# A64 register map
Vendor: Allwinner; Series: A64; File version: 0.1
CPU: CA53 0, little endian, MPU, no FPU, 0 interrupt priority bits
Registers are 32-bit, read-write, reset 0x0 unless marked. A register's access mark holds for its fields unless they carry their own. Offsets are from the block's base; [hi:lo] are bit positions; 'fields as' and 'values as' point back to an identical list.

## High_Speed_Timer
Base 0x01C60000
0x00 HS_TMR_IRQ_EN_REG — HS Timer IRQ Enable Register
  [0] HS_TMR_INT_EN — High Speed Timer Interrupt Enable. 0: No effect; 1: High Speed Timer Interval Value reached interrupt enable.
    0=No_effect; 1=High Speed Timer Interval Value reached interrupt enable
0x04 HS_TMR_IRQ_STAS_REG — HS Timer Status Register
  [0] HS_TMR_IRQ_PEND — High Speed Timer IRQ Pending. Set 1 to the bit will clear it. 0: No effect; 1: Pending, High speed timer interval value is reached.
    0=No_effect; 1=Pending, High speed timer interval value is reached
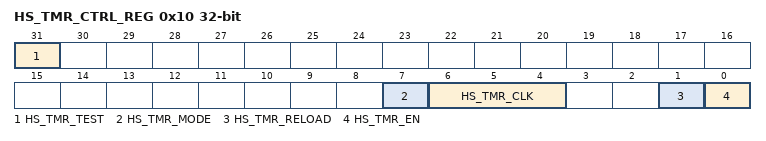
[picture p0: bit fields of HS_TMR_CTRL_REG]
0x10 HS_TMR_CTRL_REG — HS Timer Control Register
  [31] HS_TMR_TEST — High speed timer test mode. In test mode, the low register should be set to 0x1, the high register will down counter. The counter needs to be reloaded. 0: normal mode; 1: test mode.
    0=normal mode;; 1=test mode
  [7] HS_TMR_MODE — High Speed Timer mode. 0: Continuous mode. When interval value reached, the timer will not disable automatically. 1: Single mode. When interval value reached, the timer will disable automatically.
    0=Continuous mode. When interval value reached, the timer will not disable automatically.; 1=Single mode. When interval value reached, the timer will disable automatically.
  [6:4] HS_TMR_CLK — Select the pre-scale of the high speed timer clock sources. 000: /1 001: /2 010: /4 011: /8 100: /16 101: / 110: / 111: /
    0=_slash_1 (/1); 1=_slash_2 (/2); 2=_slash_4 (/4); 3=_slash_8 (/8); 4=_slash_16 (/16)
  [1] HS_TMR_RELOAD — High Speed Timer Reload. 0: No effect 1: Reload High Speed Timer Interval Value.
    0=No_effect; 1=Reload High Speed Timer Interval Value
  [0] HS_TMR_EN — High Speed Timer Enable. 0: Stop/Pause 1: Start. If the timer is started, it will reload the interval value to internal register, and the current counter will count from interval value to 0. If the current counter does not reach the zero, the timer enable bit is set to `0`, the current value counter will pause. At least wait for 2 cycles, the start bit can be set to 1. In timer pause state, the interval value register can be modified. If the timer is started again, and the Software hope the current value register to down-count from the new interval value, the reload bit and the enable bit should be set to 1 at the same time.
    0=Stop_slash_Pause (Stop/Pause); 1=Start. If the timer is started, it will reload the interval value to internal register, and the current counter will count from interval value to 0. If the current counter does not reach the zero, the timer enable bit is set to `0`, the current value counter will pause. At least wait for 2 cycles, the start bit can be set to 1. In timer pause state, the interval value register can be modified. If the timer is started again, and the Software hope the current value register to down-count from the new interval value, the reload bit and the enable bit should be set to 1 at the same time.
0x14 HS_TMR_INTV_LO_REG reset not defined — HS Timer Interval Value Low Register
  [31:0] HS_TMR_INTV_VALUE_LO — High Speed Timer Interval Value [31:0].
0x18 HS_TMR_INTV_HI_REG reset not defined — HS Timer Interval Value High Register
  [23:0] HS_TMR_INTV_VALUE_HI — High Speed Timer Interval Value [55:32].
0x1C HS_TMR_CURNT_LO_REG reset not defined — HS Timer Current Value Low Register
  [31:0] HS_TMR_CUR_VALUE_LO — High Speed Timer Current Value [31:0].
0x20 HS_TMR_CURNT_HI_REG reset not defined — HS Timer Current Value High Register
  [23:0] HS_TMR_CUR_VALUE_HI — High Speed Timer Current Value [55:32].

## KEYADC
Base 0x01C21800
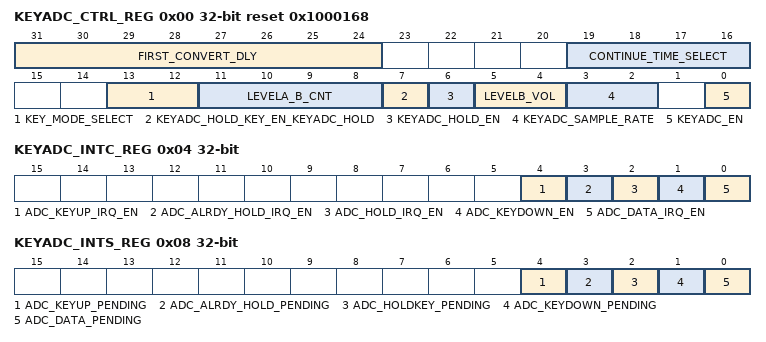
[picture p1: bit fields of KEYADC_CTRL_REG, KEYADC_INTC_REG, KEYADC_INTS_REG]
0x00 KEYADC_CTRL_REG reset 0x1000168
  [31:24] FIRST_CONVERT_DLY — FIRST_CONVERT_DLY. ADC First Convert Delay setting, ADC conversion is delayed by n samples
  [19:16] CONTINUE_TIME_SELECT — CONTINUE_TIME_SELECT. Continue Mode time select, one of 8*(N+1) sample as a valuable sample data
  [13:12] KEY_MODE_SELECT — KEY_MODE_SELECT. Key Mode Select: 00: Normal Mode 01: Single Mode 10: Continue Mode
    0=Normal Mode; 1=Single Mode; 2=Continue Mode
  [11:8] LEVELA_B_CNT — LEVELA_B_CNT. Level A to Level B time threshold select, judge ADC convert value in level A to level B in n+1 samples
  [7] KEYADC_HOLD_KEY_EN_KEYADC_HOLD — KEYADC_HOLD_KEY_EN KEYADC Hold Key Enable 0: Disable 1: Enable
    0=Disable; 1=Enable
  [6] KEYADC_HOLD_EN — KEYADC_HOLD_EN. KEYADC Sample hold Enable 0: Disable 1: Enable
    0=Disable; 1=Enable
  [5:4] LEVELB_VOL — LEVELB_VOL. Level B Corresponding Data Value setting (the real voltage value) 00: 0x3C (~1.9v) 01: 0x39 (~1.8v) 10: 0x36 (~1.7v) 11: 0x33 (~1.6v)
    0=0x3C (~1.9v); 1=0x39 (~1.8v); 2=0x36 (~1.7v); 3=0x33 (~1.6v)
  [3:2] KEYADC_SAMPLE_RATE — KEYADC_SAMPLE_RATE. KEYADC Sample Rate 00: 250 Hz 01: 125 Hz 10: 62.5 Hz 11: 32.25 Hz
    0=250 Hz; 1=125 Hz; 2=_62_point_5 (62.5 Hz); 3=_32_point_25 (32.25 Hz)
  [0] KEYADC_EN — KEYADC_EN. KEYADC enable 0: Disable 1: Enable
    0=Disable; 1=Enable
0x04 KEYADC_INTC_REG
  [all] fields
    0=Disable; 1=Enable
  [4] ADC_KEYUP_IRQ_EN — ADC Key Up IRQ Enable 0: Disable 1: Enable
  [3] ADC_ALRDY_HOLD_IRQ_EN — ADC Already Hold IRQ Enable 0: Disable 1: Enable
  [2] ADC_HOLD_IRQ_EN — ADC Hold Key IRQ Enable 0: Disable 1: Enable
  [1] ADC_KEYDOWN_EN — ADC Key Down Enable 0: Disable 1: Enable
  [0] ADC_DATA_IRQ_EN — ADC Data IRQ Enable 0: Disable 1: Enable
0x08 KEYADC_INTS_REG
  [4] ADC_KEYUP_PENDING — ADC Key up pending Bit When general key pull up, it the corresponding interrupt is enabled. 0: No IRQ 1: IRQ Pending Notes: Writing 1 to the bit will clear it and its corresponding interrupt if the interrupt is enable
    0=No_IRQ; 1=IRQ (IRQ Pending Notes: Writing 1 to the bit will clear it and its corresponding interrupt if the interrupt is enable)
  [3] ADC_ALRDY_HOLD_PENDING — ADC Already Hold Pending Bit When hold key pull down and pull the general key down, if the corresponding interrupt is enabled. 0: No IRQ 1: IRQ Pending Notes: Writing 1 to the bit will clear it and its corresponding interrupt if the interrupt is enable
    values as ADC_KEYUP_PENDING
  [2] ADC_HOLDKEY_PENDING — ADC Hold Key pending Bit When Hold key pull down, the status bit is set and the interrupt line is set if the corresponding interrupt is enabled. 0: NO IRQ 1: IRQ Pending Notes: Writing 1 to the bit will clear it and its corresponding interrupt if the interrupt is enable.
    0=NO_IRQ; 1=IRQ (IRQ Pending Notes: Writing 1 to the bit will clear it and its corresponding interrupt if the interrupt is enable.)
  [1] ADC_KEYDOWN_PENDING — ADC Key Down IRQ Pending Bit When General key pull down, the status bit is set and the interrupt line is set if the corresponding interrupt is enabled. 0: No IRQ 1: IRQ Pending Notes: Writing 1 to the bit will clear it and its corresponding interrupt if the interrupt is enable.
    0=No_IRQ; 1=IRQ (IRQ Pending Notes: Writing 1 to the bit will clear it and its corresponding interrupt if the interrupt is enable.)
  [0] ADC_DATA_PENDING — ADC Data IRQ Pending Bit 0: No IRQ 1: IRQ Pending Notes: Writing 1 to the bit will clear it and its corresponding interrupt if the interrupt is enable.
    values as ADC_KEYDOWN_PENDING
0x0C KEYADC_DATA_REG
  [5:0] KEYADC_DATA ro
